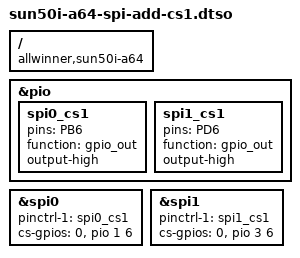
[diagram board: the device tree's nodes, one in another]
/dts-v1/;
/plugin/;

/ {
	compatible = "allwinner,sun50i-a64";

	fragment@0 {
		target = <&pio>;
		__overlay__ {
			spi0_cs1: spi0_cs1 {
				pins = "PB6";
				function = "gpio_out";
				output-high;
			};

			spi1_cs1: spi1_cs1 {
				pins = "PD6";
				function = "gpio_out";
				output-high;
			};
		};
	};

	fragment@1 {
		target = <&spi0>;
		__overlay__ {
			pinctrl-names = "default", "default";
			pinctrl-1 = <&spi0_cs1>;
			cs-gpios = <0>, <&pio 1 6 0>; /* PB6 */
		};
	};

	fragment@2 {
		target = <&spi1>;
		__overlay__ {
			pinctrl-names = "default", "default";
			pinctrl-1 = <&spi1_cs1>;
			cs-gpios = <0>, <&pio 3 6 0>; /* PD6 */
		};
	};
};
